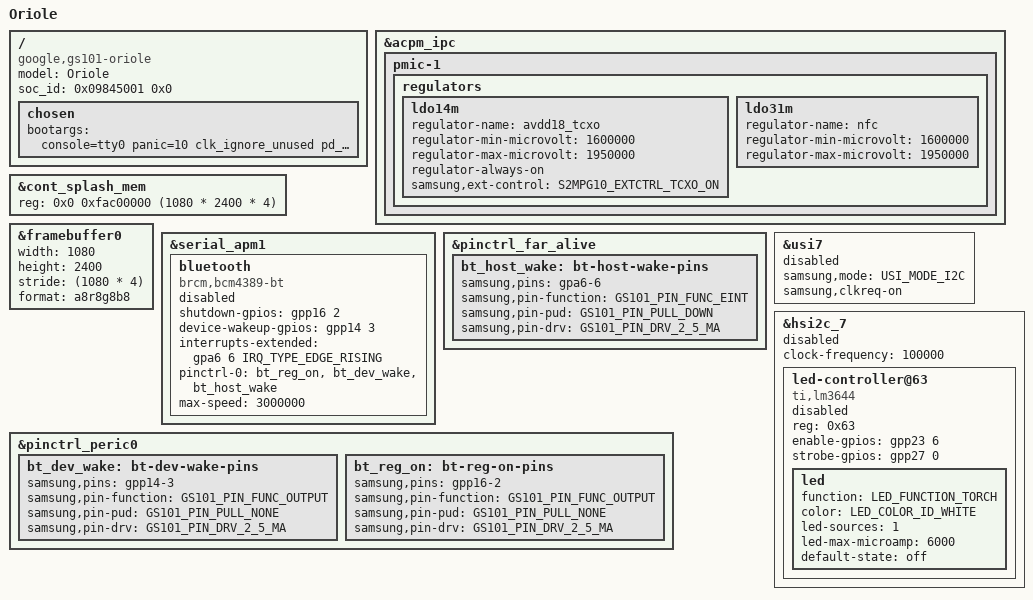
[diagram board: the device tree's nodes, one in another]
// SPDX-License-Identifier: GPL-2.0-only
/*
 * Oriole Device Tree
 *
 * Copyright 2021-2023 Google LLC
 * Copyright 2023 Linaro Ltd - <peter.griffin@linaro.org>
 */

/dts-v1/;

#include <dt-bindings/leds/common.h>
#include <dt-bindings/regulator/samsung,s2mpg10-regulator.h>
#include "gs101-pixel-common.dtsi"

/ {
	model = "Oriole";
	compatible = "google,gs101-oriole", "google,gs101";

	/*
	 * ABL picks the base DTB by soc_id (product id 0x09845000 | major
	 * revision); the factory vendor_boot carries one per revision. B0 = 1.
	 */
	soc_id = <0x09845001 0x0>;

	chosen {
		/*
		 * ABL appends its own arguments (console=null among them), so a
		 * panic is silent: panic=10 reboots instead of hanging. init hands
		 * over to the Arch root on userdata when it finds one.
		 */
		bootargs = "console=tty0 panic=10 clk_ignore_unused pd_ignore_unused rdinit=/init";
	};
};

&acpm_ipc {
	pmic-1 {
		regulators {
			ldo14m {
				/* PLL */
				regulator-name = "avdd18_tcxo";
				regulator-min-microvolt = <1600000>;
				regulator-max-microvolt = <1950000>;
				regulator-always-on;
				samsung,ext-control = <S2MPG10_EXTCTRL_TCXO_ON>;
			};

			ldo31m {
				regulator-name = "nfc";
				regulator-min-microvolt = <1600000>;
				regulator-max-microvolt = <1950000>;
			};
		};
	};
};

&cont_splash_mem {
	reg = <0x0 0xfac00000 (1080 * 2400 * 4)>;

	status = "okay";
};

&framebuffer0 {
	width = <1080>;
	height = <2400>;
	stride = <(1080 * 4)>;
	format = "a8r8g8b8";

	status = "okay";
};

/* Keep Bluetooth off until the current kernel has been qualified on Oriole. */
&serial_apm1 {
	bluetooth {
		compatible = "brcm,bcm4389-bt";
		shutdown-gpios = <&gpp16 2 GPIO_ACTIVE_HIGH>;
		device-wakeup-gpios = <&gpp14 3 GPIO_ACTIVE_HIGH>;
		interrupts-extended = <&gpa6 6 IRQ_TYPE_EDGE_RISING>;
		interrupt-names = "host-wakeup";
		pinctrl-0 = <&bt_reg_on &bt_dev_wake &bt_host_wake>;
		pinctrl-names = "default";
		max-speed = <3000000>;
		status = "disabled";
	};
};

/* Bluetooth control lines match the shared gs101 wiring. */
&pinctrl_far_alive {
	bt_host_wake: bt-host-wake-pins {
		samsung,pins = "gpa6-6";
		samsung,pin-function = <GS101_PIN_FUNC_EINT>;
		samsung,pin-pud = <GS101_PIN_PULL_DOWN>;
		samsung,pin-drv = <GS101_PIN_DRV_2_5_MA>;
	};
};

&pinctrl_peric0 {
	bt_dev_wake: bt-dev-wake-pins {
		samsung,pins = "gpp14-3";
		samsung,pin-function = <GS101_PIN_FUNC_OUTPUT>;
		samsung,pin-pud = <GS101_PIN_PULL_NONE>;
		samsung,pin-drv = <GS101_PIN_DRV_2_5_MA>;
	};

	bt_reg_on: bt-reg-on-pins {
		samsung,pins = "gpp16-2";
		samsung,pin-function = <GS101_PIN_FUNC_OUTPUT>;
		samsung,pin-pud = <GS101_PIN_PULL_NONE>;
		samsung,pin-drv = <GS101_PIN_DRV_2_5_MA>;
	};
};

/*
 * Rear flash wiring from Google's GPL gs101-oriole-camera.dtsi. Keep the
 * external strobe low; torch only, one sink with a conservative 6 mA cap.
 * Enable only after a guarded qualification on the matching kernel.
 */
&usi7 {
	samsung,mode = <USI_MODE_I2C>;
	samsung,clkreq-on;
	status = "disabled";
};

&hsi2c_7 {
	clock-frequency = <100000>;
	status = "disabled";

	led-controller@63 {
		compatible = "ti,lm3644";
		reg = <0x63>;
		enable-gpios = <&gpp23 6 GPIO_ACTIVE_HIGH>;
		strobe-gpios = <&gpp27 0 GPIO_ACTIVE_HIGH>;
		status = "disabled";

		led {
			function = LED_FUNCTION_TORCH;
			color = <LED_COLOR_ID_WHITE>;
			led-sources = <1>;
			led-max-microamp = <6000>;
			default-state = "off";
		};
	};
};
